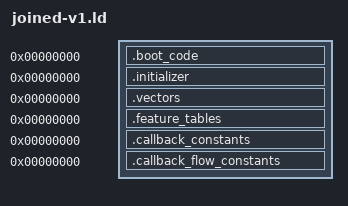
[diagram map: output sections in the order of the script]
OUTPUT_ARCH(riscv)
SECTIONS
{
 .boot_code 0 : SUBALIGN(2) { *(.boot_code)
  *(.text.tsl9_rom_dependency_entry_81de)
  *(.text.tsl9_rom_driver_external_9792)
  *(.text.tsl9_rom_dependency_block_9798)
  *(.text.tsl9_rom_dependency_block_979a)
  *(.text.tsl9_rom_dependency_entry_9f74)
  *(.text.tsl9_rom_driver_external_9fc2)
  *(.text.tsl9_rom_dependency_entry_a204)
  *(.text.tsl9_rom_dependency_block_a20e)
  *(.text.tsl9_rom_dependency_block_a212)
  *(.text.tsl9_rom_dependency_block_a216)
  *(.text.tsl9_rom_dependency_block_a21a)
  *(.text.tsl9_rom_dependency_block_a228)
  *(.text.tsl9_rom_dependency_block_a22e)
  *(.text.tsl9_rom_dependency_block_a230)
  *(.text.tsl9_rom_dependency_block_a246)
  *(.text.tsl9_rom_dependency_block_a24a)
  *(.text.tsl9_rom_dependency_block_a250)
  *(.text.tsl9_rom_dependency_block_a254)
  *(.text.tsl9_rom_dependency_block_a260)
  *(.text.tsl9_rom_dependency_block_a264)
  *(.text.tsl9_rom_dependency_block_a26a)
  *(.text.tsl9_rom_dependency_block_a26e)
  *(.text.tsl9_rom_dependency_block_a274)
  *(.text.tsl9_rom_dependency_block_a27a)
  *(.text.tsl9_rom_dependency_block_a282)
  *(.text.tsl9_rom_dependency_block_a286)
  *(.text.tsl9_rom_dependency_block_a28e)
  *(.text.tsl9_rom_dependency_block_a294)
  *(.text.tsl9_rom_dependency_block_a298)
  *(.text.tsl9_rom_dependency_block_a2a0)
  *(.text.tsl9_rom_dependency_block_a2a8)
  *(.text.tsl9_rom_dependency_block_a2aa)
  *(.text.tsl9_rom_dependency_block_a2b6)
  *(.text.tsl9_rom_dependency_block_a2be)
  *(.text.tsl9_rom_dependency_block_a2c4)
  *(.text.tsl9_rom_dependency_block_a2c8)
  *(.text.tsl9_rom_dependency_block_a2ca)
  *(.text.tsl9_rom_dependency_block_a2d2)
  *(.text.tsl9_rom_dependency_block_a2dc)
  *(.text.tsl9_rom_dependency_block_a2e0)
  *(.text.tsl9_rom_dependency_block_a2e4)
  *(.text.tsl9_rom_driver_external_a2ee)
  *(.text.tsl9_rom_dependency_block_a2fc)
  *(.text.tsl9_rom_dependency_block_a302)
  *(.text.tsl9_rom_dependency_block_a306)
  *(.text.tsl9_rom_dependency_block_a30e)
  *(.text.tsl9_rom_dependency_block_a312)
  *(.text.tsl9_rom_dependency_block_a316)
  *(.text.tsl9_rom_dependency_block_a31c)
  *(.text.tsl9_rom_dependency_block_a31e)
  *(.text.tsl9_rom_dependency_block_a320)
  *(.text.tsl9_rom_dependency_block_a332)
  *(.text.tsl9_rom_dependency_block_a364)
  *(.text.tsl9_rom_dependency_block_a372)
  *(.text.tsl9_rom_driver_external_abf2)
 }
 .initializer 0 : SUBALIGN(4) { *(.initializer) }
 .vectors 0 : SUBALIGN(4) { *(.vectors) }
 .feature_tables 0 : SUBALIGN(4) { *(.feature_tables) }
 .callback_constants 0 : SUBALIGN(4) { *(.callback_constants) }
 .callback_flow_constants 0 : SUBALIGN(4) { *(.callback_flow_constants) }
 /DISCARD/ : { *(.comment) *(.riscv.attributes) *(.llvm_addrsig) }
}
